# MB9BF32xT register map
File version: 1.0
Registers are 32-bit, read-write, reset 0x0 unless marked. A register's access mark holds for its fields unless they carry their own. Offsets are from the block's base; lines under a group give offsets from that group; [hi:lo] are bit positions; {n}, {i} and the like mark numbered series; 'fields as' and 'values as' point back to an identical list; <NAME> marks a mode.

## Memory map
0x40000000 FLASH_IF blocks up to offset 0x104 — peripheral FLASH_IF
0x40000200 UNIQUE_ID blocks up to offset 0x8 — peripheral UNIQUE_ID
0x40010000 CRG blocks up to offset 0x69 — peripheral CRG
0x40011000 HWWDT blocks up to offset 0xC04 — peripheral HWWDT
0x40012000 SWWDT blocks up to offset 0xC04 — peripheral SWWDT
0x40015000 DTIM blocks up to offset 0x3C — peripheral DTIM
0x40020000 MFT0 blocks up to offset 0xC2 — peripheral MFT0
0x40024000 MFT_PPG blocks up to offset 0x381 — peripheral MFT_PPG
0x40025000 BT0 blocks up to offset 0x12 — peripheral BT0
0x40025040 BT1 blocks up to offset 0x12
0x40025080 BT2 blocks up to offset 0x12
0x400250C0 BT3 blocks up to offset 0x12
0x40025100 BTIOSEL03 size 0x2 — peripheral BTIOSEL03
0x40025200 BT4 blocks up to offset 0x12
0x40025240 BT5 blocks up to offset 0x12
0x40025280 BT6 blocks up to offset 0x12
0x400252C0 BT7 blocks up to offset 0x12
0x40025300 BTIOSEL47 blocks up to offset 0x2 — peripheral BTIOSEL47
0x40025400 BT8 blocks up to offset 0x12
0x40025440 BT9 blocks up to offset 0x12
0x40025480 BT10 blocks up to offset 0x12
0x400254C0 BT11 blocks up to offset 0x12
0x40025500 BTIOSEL8B size 0x2 — peripheral BTIOSEL8B
0x40025600 BT12 blocks up to offset 0x12
0x40025640 BT13 blocks up to offset 0x12
0x40025680 BT14 blocks up to offset 0x12
0x400256C0 BT15 blocks up to offset 0x12
0x40025700 BTIOSELCF size 0x2 — peripheral BTIOSELCF
0x40025F00 SBSSR blocks up to offset 0xFE — peripheral SBSSR
0x40026000 QPRC0 blocks up to offset 0x40 — peripheral QPRC0
0x40026040 QPRC1 blocks up to offset 0x40
0x40027000 ADC0 blocks up to offset 0x3E — peripheral ADC0
0x40027100 ADC1 blocks up to offset 0x3E
0x40028000 DAC blocks up to offset 0x7 — peripheral DAC
0x4002E000 CRTRIM blocks up to offset 0x10 — peripheral CRTRIM
0x40030000 EXTI blocks up to offset 0x19 — peripheral EXTI
0x40031000 INTREQ blocks up to offset 0x218 — peripheral INTREQ
0x40033000 GPIO size 0x740 — peripheral GPIO
0x40034000 HDMICEC0 blocks up to offset 0x66 — peripheral HDMICEC0
0x40034100 HDMICEC1 blocks up to offset 0x66
0x40035000 LVD blocks up to offset 0x11 — peripheral LVD
0x40035100 DS blocks up to offset 0x816 — peripheral DS
0x40036000 USBCLK blocks up to offset 0x31 — peripheral USBCLK
0x40038000 MFS0 blocks up to offset 0x1E — peripheral MFS0
{0x40038000+0x100*n} MFS{n} blocks up to offset 0x1E (n=1..15)
0x40039000 CRC blocks up to offset 0x10 — peripheral CRC
0x4003A000 WC blocks up to offset 0x15 — peripheral WC
0x4003B000 RTC blocks up to offset 0x31 — peripheral RTC
0x4003F000 EXBUS blocks up to offset 0x304 — peripheral EXBUS
0x40040000 USB0 blocks up to offset 0x2176 — peripheral USB0
0x40060000 DMAC blocks up to offset 0x90 — peripheral DMAC

## Interrupts
0 CSV (CRG)
1 SWDT (SWWDT)
2 LVD
3 WFG (MFT0)
4 EXTINT0_7 (EXTI)
5 EXTINT8_31 (EXTI)
6 DTIM_QDU (DTIM)
{2n+7} MFS{n}_{n+8}_RX (MFS{n}, MFS{n+8}) (n=0..7)
{2n+8} MFS{n}_{n+8}_TX (MFS{n}, MFS{n+8}) (n=0..7)
23 PPG (MFT_PPG)
24 OSC_PLL_WC_RTC (CRG)
25 ADC0
26 ADC1
28 FRTIM (MFT0)
29 INCAP (MFT0)
30 OUTCOMP (MFT0)
31 BTIM0_7 (BT0)
34 USB0F (USB0)
35 USB0F_USB0H (USB0)
36 HDMICEC0
37 HDMICEC1
{n+38} DMAC{n} (DMAC) (n=0..7)

## FLASH_IF — peripheral FLASH_IF
Base 0x40000000
0x04 FRWTR
  [1:0] RWT
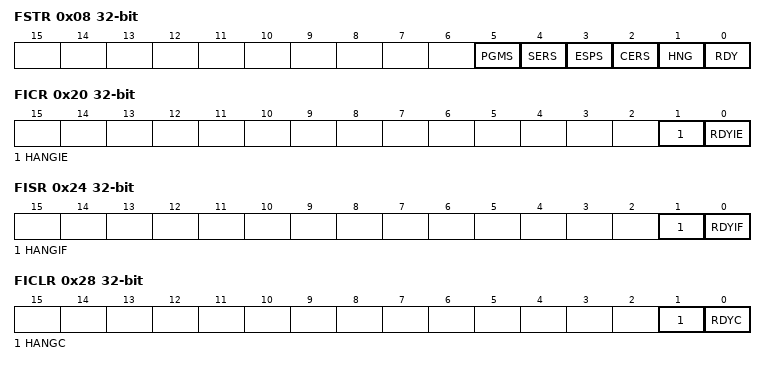
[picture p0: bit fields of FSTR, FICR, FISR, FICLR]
0x08 FSTR ro
  [5] PGMS, [4] SERS, [3] ESPS, [2] CERS, [1] HNG, [0] RDY
0x20 FICR
  [1] HANGIE, [0] RDYIE
0x24 FISR
  [1] HANGIF, [0] RDYIF
0x28 FICLR wo
  [1] HANGC rw, [0] RDYC rw
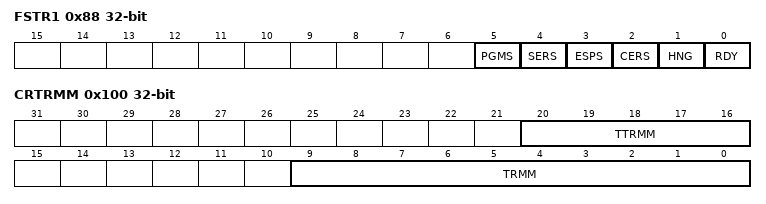
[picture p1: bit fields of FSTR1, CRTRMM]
0x88 FSTR1
  [5] PGMS ro, [4] SERS ro, [3] ESPS ro, [2] CERS ro, [1] HNG ro, [0] RDY ro
0x100 CRTRMM ro reset not defined
  [20:16] TTRMM, [9:0] TRMM

## UNIQUE_ID — peripheral UNIQUE_ID
Base 0x40000200
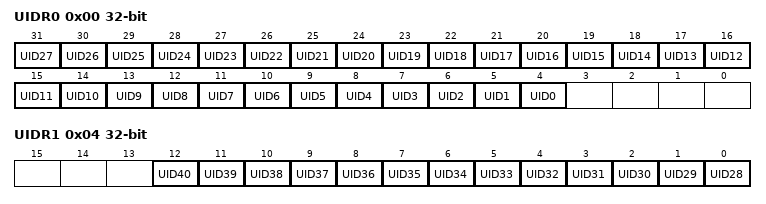
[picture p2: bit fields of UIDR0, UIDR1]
0x00 UIDR0 ro
  [n+4] UID{n} (n=0..27)
0x04 UIDR1 ro
  [n-28] UID{n} (n=28..40)

## Notices in the file
Licence Terms
FUJITSU SEMICONDUCTOR LIMITED (gLICENSORh) hereby grants and
you (gLICENSEEh) hereby accept a non transferable, non-exclusive
licence to use and copy the deliverables (gDeliverablesh) solely for
the purpose of; (i) developing LICENSEEfs development tools and
distributing such development tools to third parties; (ii) generating
derivative representations of the Deliverables to develop and debug
software for LICENSORfs targeted devices or device series identified
within the Deliverables, (together the gPurposeh) under the following
terms and conditions:
1. Ownership.
The Deliverables are the property of LICENSOR. LICENSEE acquires no
right, title or interest in the Deliverables other than the licence
rights granted herein.
2. Use.
LICENSEE shall only be permitted to use the Deliverables for the
Purpose. LICENSEE shall not reverse engineer, decompile or
disassemble the Deliverables, in whole or in part.
3. Copies.
All copies of the Deliverables must bear the same notice(s) contained
on the original copies of the Deliverables.
4. No Warranty.
THE DELIVERABLES ARE PROVIDED gAS ISh AND ANY EXPRESS, IMPLIED OR
STATUTORY WARRANTIES, INCLUDING, BUT NOT LIMITED TO, THE IMPLIED
WARRANTIES OF MERCHANTABILITY, SATISFACTORY QUALITY AND FITNESS FOR
A PARTICULAR PURPOSE ARE DISCLAIMED.
IN NO EVENT SHALL LICENSOR BE LIABLE FOR ANY DIRECT, INDIRECT,
INCIDENTAL, SPECIAL, EXEMPLARY, OR CONSEQUENTIAL DAMAGES HOWEVER CAUSED
AND ON ANY THEORY OF LIABILITY, WHETHER IN CONTRACT, STRICT LIABILITY,
OR TORT (INCLUDING NEGLIGENCE OR OTHERWISE) ARISING IN ANY WAY OUT OF
THE USE OF THE DELIVERABLES, EVEN IF ADVISED OF THE POSSIBILITY OF SUCH
DAMAGE.
LICENSEE EXPRESSLY ASSUMES ALL LIABILITIES AND RISKS, FOR USE OR
OPERATION OF THE DELIVERABLES.
5.In the event that LICENSEE receives early access to the Deliverables,
LICENSEE acknowledges and agrees that;
(a) notwithstanding the licence grants above, LICENSEE shall only be
permitted to use the Deliverables solely internally for evaluation and
providing feedback to LICENSOR;
(b) except with respect to the limited licence grants in 5(a), LICENSEE
shall be subject to all of the terms and conditions set out above; and
(c) the Deliverables are confidential information and LICENSEE shall
maintain in confidence the Deliverables and apply security measures no
less stringent than the measures that LICENSEE applies to its own like
information, but not less than a reasonable degree of care, to prevent
unauthorised disclosure and use of the Deliverables.
